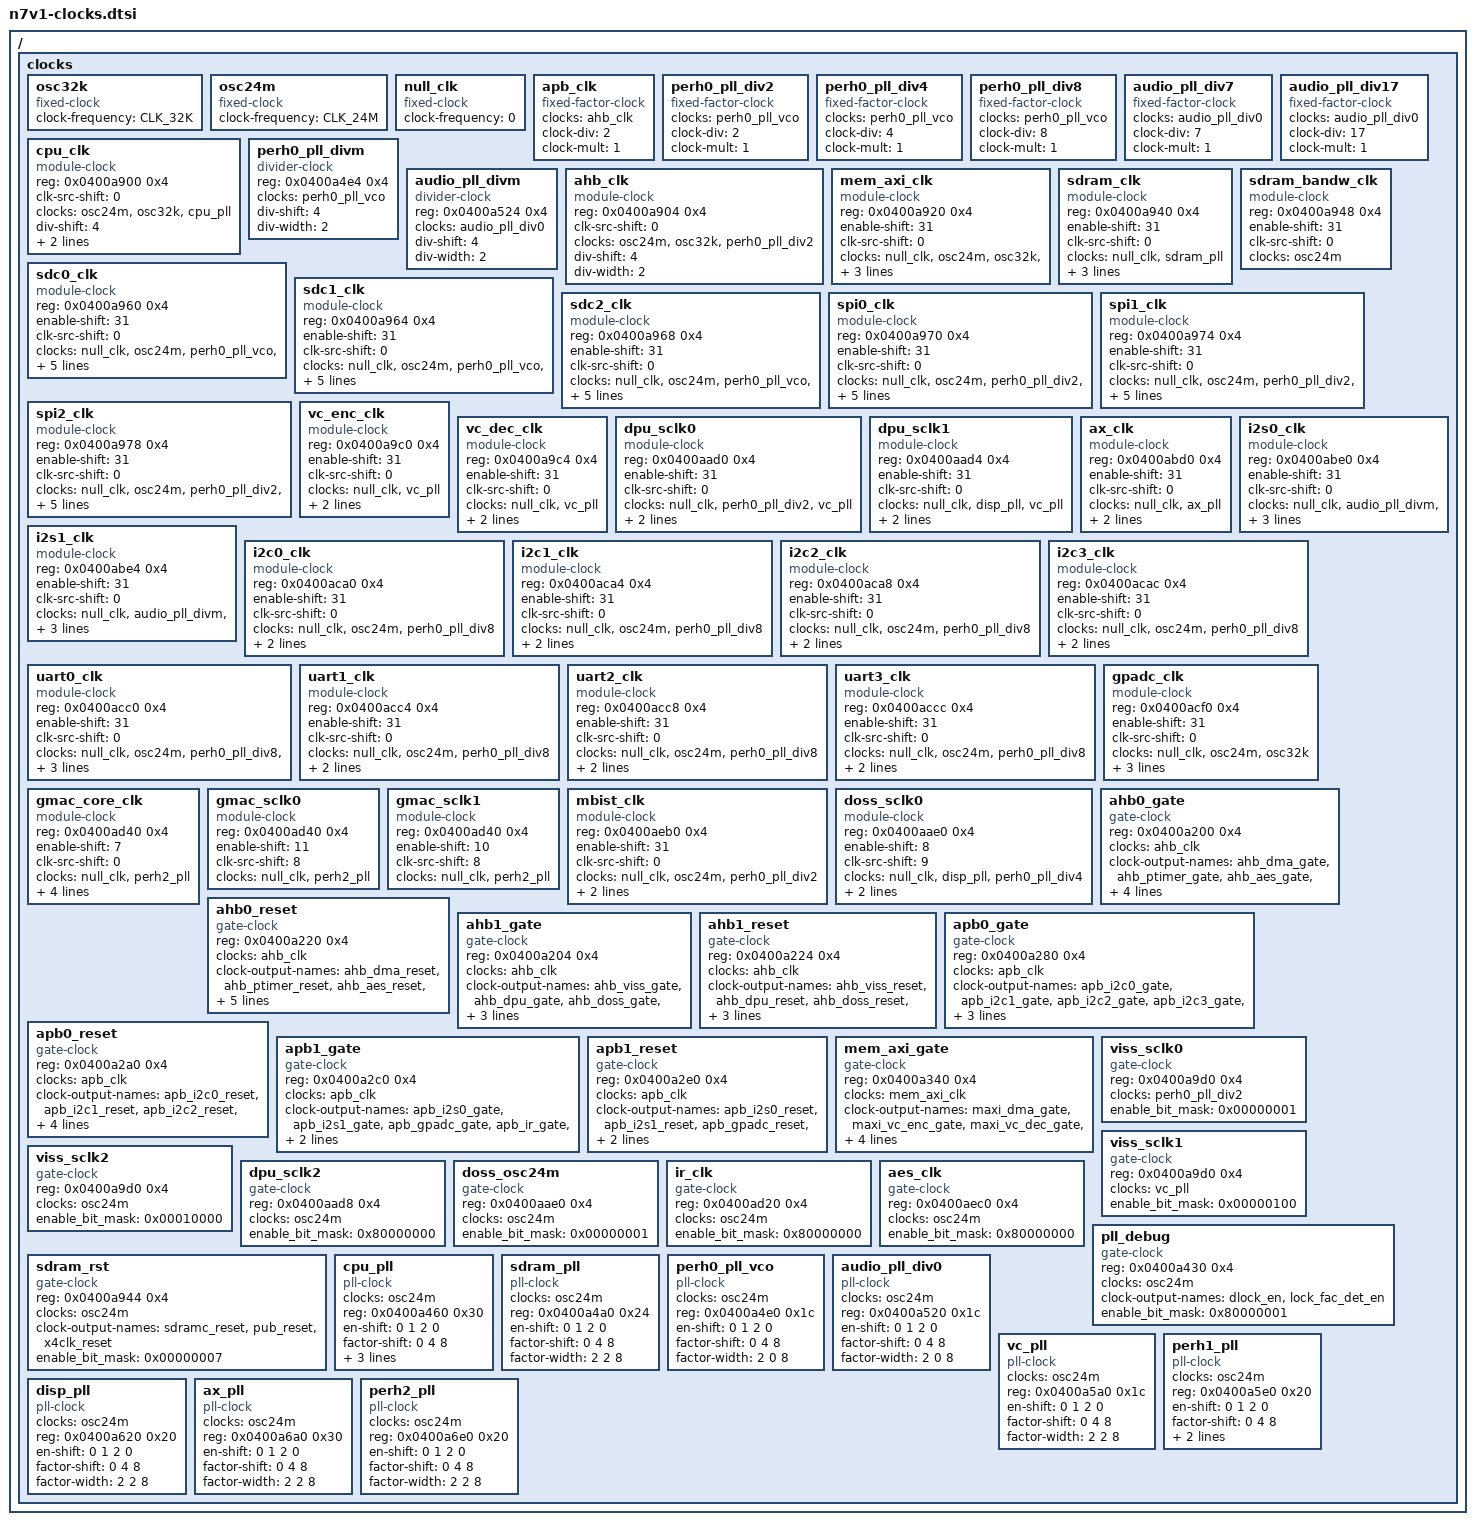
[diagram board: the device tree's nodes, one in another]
/*
 * lombo-n7v1-clocks.dts - clock device tree configurations for N7V1 platform
 *
 * Copyright (C) 2016-2018, LomboTech Co.Ltd.
 * Author: lomboswer <lomboswer@lombotech.com>
 *
 * This program is free software; you can redistribute it and/or modify
 * it under the terms of the GNU General Public License version 2 as
 * published by the Free Software Foundation.
 *
 * This program is distributed in the hope that it will be useful,
 * but WITHOUT ANY WARRANTY; without even the implied warranty of
 * MERCHANTABILITY or FITNESS FOR A PARTICULAR PURPOSE.  See the
 * GNU General Public License for more details.
 *
 * You should have received a copy of the GNU General Public License along
 * with this program; if not, write to the Free Software Foundation, Inc.,
 * 51 Franklin Street, Fifth Floor, Boston, MA 02110-1301 USA.
 */

/ {

/*
 * note: these clocks are not realized now:
 *    hfeosc xtal control register(0x420)
 *    mbias control register(0x424)
 *    usb phy reset control register(0xce0)
 */

clocks {
	#address-cells = <1>;
	#size-cells = <1>;
	ranges;

	/*
	 * fix rate clocks - osc
	 */
	osc32k: osc32k {
		compatible = "fixed-clock";
		#clock-cells = <0>;
		clock-frequency = <CLK_32K>;
	};

	osc24m: osc24m {
		compatible = "fixed-clock";
		#clock-cells = <0>;
		clock-frequency = <CLK_24M>;
	};

	/* used as other clocks' parent, not real clock */
	null_clk: null_clk {
		compatible = "fixed-clock";
		#clock-cells = <0>;
		clock-frequency = <0>;
	};

	/*
	 * fix factor clocks
	 */
	apb_clk: apb_clk {
		compatible = "fixed-factor-clock";
		clocks = <&ahb_clk>;
		#clock-cells = <0>;
		clock-div = <2>;
		clock-mult = <1>;
	};

	perh0_pll_div2: perh0_pll_div2 {
		compatible = "fixed-factor-clock";
		clocks = <&perh0_pll_vco>;
		#clock-cells = <0>;
		clock-div = <2>;
		clock-mult = <1>;
	};

	perh0_pll_div4: perh0_pll_div4 {
		compatible = "fixed-factor-clock";
		clocks = <&perh0_pll_vco>;
		#clock-cells = <0>;
		clock-div = <4>;
		clock-mult = <1>;
	};

	perh0_pll_div8: perh0_pll_div8 {
		compatible = "fixed-factor-clock";
		clocks = <&perh0_pll_vco>;
		#clock-cells = <0>;
		clock-div = <8>;
		clock-mult = <1>;
	};

	audio_pll_div7: audio_pll_div7 {
		compatible = "fixed-factor-clock";
		clocks = <&audio_pll_div0>;
		#clock-cells = <0>;
		clock-div = <7>;
		clock-mult = <1>;
	};

	audio_pll_div17: audio_pll_div17 {
		compatible = "fixed-factor-clock";
		clocks = <&audio_pll_div0>;
		#clock-cells = <0>;
		clock-div = <17>;
		clock-mult = <1>;
	};

	/*
	 * cpu and bus clocks
	 */
	cpu_clk: cpu_clk {
		compatible = "module-clock";
		reg = <0x0400a900 0x4>;
		#clock-cells = <0>;
		clk-src-shift = <0>;
		clocks = <&osc24m>, <&osc32k>, <&cpu_pll>;
		div-shift = <4>;
		div-width = <2>;
		div-table = <0 1
			     1 2
			     2 4>;
	};

	perh0_pll_divm: perh0_pll_divm {
		compatible = "divider-clock";
		reg = <0x0400a4e4 0x4>;
		#clock-cells = <0>;
		clocks = <&perh0_pll_vco>;
		div-shift = <4>;
		div-width = <2>;
	};

	audio_pll_divm: audio_pll_divm {
		compatible = "divider-clock";
		reg = <0x0400a524 0x4>;
		#clock-cells = <0>;
		clocks = <&audio_pll_div0>;
		div-shift = <4>;
		div-width = <2>;
	};

	/* apb_clk is fix-divider-clock */

	/*
	 * module  clocks
	 *
	 * xxx_clk: xxx_clk {			clock name
	 *	compatible = "module-clock";	identify string, should not be changed
	 *	reg = <0x0400a900 0x4>;		the register addr and len
	 *	#clock-cells = <0>;		should be 0
	 *	enable-shift = <xxx>;		optional, enable bit's offset
	 *	clk-src-shift = <0>;		the src clock select bit's offset
	 *	clocks = <&src_clk1>, <&src_clk2>;	parent clocks list
	 *
	 * the below configurations are specific for different modules:
	 *   for clocks with only div0:
	 *	div-shift = <div0_shift>;	bit offset of div0
	 *	div-width = <div0_width>;	bit width of div0
	 *	div-table = <val div val div...>;	optional, div0 table
	 *	  note:	1. if div-table not exist, the division value default
	 *			is (div_val+1), while div_val is read from reg
	 *
	 *   for clocks with div0 and div1:
	 *	div-shift = <div0_shift div1_shift>;	bit offset of div0 and div1
	 *	div-width = <div0_width div1_width>;	bit width of div0 and div1
	 *	div-table0 = <val div val div...>;	optional, div0 table
	 *	div-table1 = <val div val div...>;	optional, div1 table
	 *	  note:	1. if div-table not exist, the division value default
	 *			is (div_val+1), while div_val is read from reg
	 *	freq-div-table = <rate parent_rate div0 div1
	 *		          rate parent_rate div0 div1 ...>;   optional
	 *	  note:	1. freq-div-table is optional
	 *		2. div0/div1 is the division value calculated from the orignal
	 *			reg bits value, but it's NOT the orignal bits value
	 *			eg. div0 is 8 and the orignal bits value is 3 (2^3=8)
	 * };
	 */
	ahb_clk: ahb_clk {
		compatible = "module-clock";
		reg = <0x0400a904 0x4>;
		#clock-cells = <0>;
		clk-src-shift = <0>;
		clocks = <&osc24m>, <&osc32k>,
			<&perh0_pll_div2>;
		div-shift = <4>;
		div-width = <2>;
	};

	mem_axi_clk: mem_axi_clk {
		compatible = "module-clock";
		reg = <0x0400a920 0x4>;
		#clock-cells = <0>;
		enable-shift = <31>;
		clk-src-shift = <0>;
		clocks = <&null_clk>, <&osc24m>,
			<&osc32k>, <&perh0_pll_vco>;
		div-shift = <4>;
		div-width = <2>;
	};

	sdram_clk: sdram_clk {
		compatible = "module-clock";
		reg = <0x0400a940 0x4>;
		#clock-cells = <0>;
		enable-shift = <31>;
		clk-src-shift = <0>;
		clocks = <&null_clk>, <&sdram_pll>;
		div-shift = <4>;
		div-width = <2>;
		div-table = <0 1
			     1 2
			     2 4>;
	};

	sdram_bandw_clk: sdram_bandw_clk {
		compatible = "module-clock";
		reg = <0x0400a948 0x4>;
		#clock-cells = <0>;
		enable-shift = <31>;
		clk-src-shift = <0>;
		clocks = <&osc24m>;
	};

	sdc0_clk: sdc0_clk {
		compatible = "module-clock";
		reg = <0x0400a960 0x4>;
		#clock-cells = <0>;
		enable-shift = <31>;
		clk-src-shift = <0>;
		clocks = <&null_clk>, <&osc24m>,
			<&perh0_pll_vco>, <&perh1_pll>;
		div-shift = <4 8>;
		div-width = <4 4>;
		freq-div-table = <200000    24000000    12  10
				  240000    24000000    10  10
				  400000    24000000    6   10
				  600000    24000000    5   8
				  800000    24000000    5   6
				  24000000  24000000    1   1
				  30000000  600000000   10  2
				  50000000  600000000   6   2
				  60000000  600000000   5   2
				  75000000  600000000   4   2
				  100000000 600000000   3   2
				  104000000 600000000   3   2
				  120000000 600000000   5   1
				  150000000 600000000   2   2
				  200000000 600000000   3   1
				  300000000 600000000   1   2
				  30000000  1188000000  5   8
				  40000000  1188000000  5   6
				  48000000  1188000000  5   5
				  50000000  1188000000  6   4
				  60000000  1188000000  5   4
				  66000000  1188000000  3   6
				  74000000  1188000000  4   4
				  80000000  1188000000  15  1
				  92000000  1188000000  13  1
				  100000000 1188000000  3   4
				  104000000 1188000000  3   4
				  108000000 1188000000  11  1
				  120000000 1188000000  5   2
				  132000000 1188000000  9   1
				  150000000 1188000000  8   1
				  170000000 1188000000  7   1
				  200000000 1188000000  6   1
				  240000000 1188000000  5   1
				  300000000 1188000000  4   1
				  400000000 1188000000  3   1>;
	};

	sdc1_clk: sdc1_clk {
		compatible = "module-clock";
		reg = <0x0400a964 0x4>;
		#clock-cells = <0>;
		enable-shift = <31>;
		clk-src-shift = <0>;
		clocks = <&null_clk>, <&osc24m>,
			<&perh0_pll_vco>, <&perh1_pll>;
		div-shift = <4 8>;
		div-width = <4 4>;
		freq-div-table = <200000    24000000    12  10
				  240000    24000000    10  10
				  400000    24000000    6   10
				  600000    24000000    5   8
				  800000    24000000    5   6
				  24000000  24000000    1   1
				  30000000  600000000   10  2
				  50000000  600000000   6   2
				  60000000  600000000   5   2
				  75000000  600000000   4   2
				  100000000 600000000   3   2
				  104000000 600000000   3   2
				  120000000 600000000   5   1
				  150000000 600000000   2   2
				  200000000 600000000   3   1
				  300000000 600000000   1   2
				  30000000  1188000000  5   8
				  40000000  1188000000  5   6
				  48000000  1188000000  5   5
				  50000000  1188000000  6   4
				  60000000  1188000000  5   4
				  66000000  1188000000  3   6
				  74000000  1188000000  4   4
				  80000000  1188000000  15  1
				  92000000  1188000000  13  1
				  100000000 1188000000  3   4
				  104000000 1188000000  3   4
				  108000000 1188000000  11  1
				  120000000 1188000000  5   2
				  132000000 1188000000  9   1
				  150000000 1188000000  8   1
				  170000000 1188000000  7   1
				  200000000 1188000000  6   1
				  240000000 1188000000  5   1
				  300000000 1188000000  4   1
				  400000000 1188000000  3   1>;
	};

	sdc2_clk: sdc2_clk {
		compatible = "module-clock";
		reg = <0x0400a968 0x4>;
		#clock-cells = <0>;
		enable-shift = <31>;
		clk-src-shift = <0>;
		clocks = <&null_clk>, <&osc24m>,
			<&perh0_pll_vco>, <&perh1_pll>;
		div-shift = <4 8>;
		div-width = <4 4>;
		freq-div-table = <200000    24000000    12  10
				  240000    24000000    10  10
				  400000    24000000    6   10
				  600000    24000000    5   8
				  800000    24000000    5   6
				  24000000  24000000    1   1
				  30000000  600000000   10  2
				  50000000  600000000   6   2
				  60000000  600000000   5   2
				  75000000  600000000   4   2
				  100000000 600000000   3   2
				  104000000 600000000   3   2
				  120000000 600000000   5   1
				  150000000 600000000   2   2
				  200000000 600000000   3   1
				  300000000 600000000   1   2
				  30000000  1188000000  5   8
				  40000000  1188000000  5   6
				  48000000  1188000000  5   5
				  50000000  1188000000  6   4
				  60000000  1188000000  5   4
				  66000000  1188000000  3   6
				  74000000  1188000000  4   4
				  80000000  1188000000  15  1
				  92000000  1188000000  13  1
				  100000000 1188000000  3   4
				  104000000 1188000000  3   4
				  108000000 1188000000  11  1
				  120000000 1188000000  5   2
				  132000000 1188000000  9   1
				  150000000 1188000000  8   1
				  170000000 1188000000  7   1
				  200000000 1188000000  6   1
				  240000000 1188000000  5   1
				  300000000 1188000000  4   1
				  400000000 1188000000  3   1>;
	};

	spi0_clk: spi0_clk {
		compatible = "module-clock";
		reg = <0x0400a970 0x4>;
		#clock-cells = <0>;
		enable-shift = <31>;
		clk-src-shift = <0>;
		clocks = <&null_clk>, <&osc24m>,
			<&perh0_pll_div2>, <&perh1_pll>;
		div-shift = <4 8>;
		div-width = <3 4>;
		freq-div-table = <4000000    24000000   1   6
				  6000000    24000000   1   4
				  8000000    24000000   1   3
				  12000000   24000000   1   2
				  24000000   24000000   1   1
				  25000000   594000000  6   4
				  30000000   594000000  5   4
				  37500000   594000000  4   4
				  40000000   594000000  3   5
				  50000000   594000000  3   4
				  60000000   594000000  5   2
				  75000000   594000000  2   4
				  100000000  594000000  3   2
				  120000000  594000000  1   5
				  150000000  594000000  1   4
				  200000000  594000000  1   3>;
	};

	spi1_clk: spi1_clk {
		compatible = "module-clock";
		reg = <0x0400a974 0x4>;
		#clock-cells = <0>;
		enable-shift = <31>;
		clk-src-shift = <0>;
		clocks = <&null_clk>, <&osc24m>,
			<&perh0_pll_div2>, <&perh1_pll>;
		div-shift = <4 8>;
		div-width = <3 4>;
		freq-div-table = <4000000    24000000   1   6
				  6000000    24000000   1   4
				  8000000    24000000   1   3
				  12000000   24000000   1   2
				  24000000   24000000   1   1
				  25000000   594000000  6   4
				  30000000   594000000  5   4
				  37500000   594000000  4   4
				  40000000   594000000  3   5
				  50000000   594000000  3   4
				  60000000   594000000  5   2
				  75000000   594000000  2   4
				  100000000  594000000  3   2
				  120000000  594000000  1   5
				  150000000  594000000  1   4
				  200000000  594000000  1   3>;
	};

	spi2_clk: spi2_clk {
		compatible = "module-clock";
		reg = <0x0400a978 0x4>;
		#clock-cells = <0>;
		enable-shift = <31>;
		clk-src-shift = <0>;
		clocks = <&null_clk>, <&osc24m>,
			<&perh0_pll_div2>, <&perh1_pll>;
		div-shift = <4 8>;
		div-width = <3 4>;
		freq-div-table = <4000000    24000000   1   6
				  6000000    24000000   1   4
				  8000000    24000000   1   3
				  12000000   24000000   1   2
				  24000000   24000000   1   1
				  25000000   594000000  6   4
				  30000000   594000000  5   4
				  37500000   594000000  4   4
				  40000000   594000000  3   5
				  50000000   594000000  3   4
				  60000000   594000000  5   2
				  75000000   594000000  2   4
				  100000000  594000000  3   2
				  120000000  594000000  1   5
				  150000000  594000000  1   4
				  200000000  594000000  1   3>;
	};

	vc_enc_clk: vc_enc_clk {
		compatible = "module-clock";
		reg = <0x0400a9c0 0x4>;
		#clock-cells = <0>;
		enable-shift = <31>;
		clk-src-shift = <0>;
		clocks = <&null_clk>, <&vc_pll>;
		div-shift = <4>;
		div-width = <4>;
	};

	vc_dec_clk: vc_dec_clk {
		compatible = "module-clock";
		reg = <0x0400a9c4 0x4>;
		#clock-cells = <0>;
		enable-shift = <31>;
		clk-src-shift = <0>;
		clocks = <&null_clk>, <&vc_pll>;
		div-shift = <4>;
		div-width = <4>;
	};

	/* viss_sclk0/1/2 are gate clock */

	dpu_sclk0: dpu_sclk0 {
		compatible = "module-clock";
		reg = <0x0400aad0 0x4>;
		#clock-cells = <0>;
		enable-shift = <31>;
		clk-src-shift = <0>;
		clocks = <&null_clk>, <&perh0_pll_div2>, <&vc_pll>;
		div-shift = <4>;
		div-width = <4>;
	};

	dpu_sclk1: dpu_sclk1 {
		compatible = "module-clock";
		reg = <0x0400aad4 0x4>;
		#clock-cells = <0>;
		enable-shift = <31>;
		clk-src-shift = <0>;
		clocks = <&null_clk>, <&disp_pll>, <&vc_pll>;
		div-shift = <4>;
		div-width = <4>;
	};

	/* dpu_sclk2 is gate clock */

	ax_clk: ax_clk {
		compatible = "module-clock";
		reg = <0x0400abd0 0x4>;
		#clock-cells = <0>;
		enable-shift = <31>;
		clk-src-shift = <0>;
		clocks = <&null_clk>, <&ax_pll>;
		div-shift = <4>;
		div-width = <3>;
	};

	i2s0_clk: i2s0_clk {
		compatible = "module-clock";
		reg = <0x0400abe0 0x4>;
		#clock-cells = <0>;
		enable-shift = <31>;
		clk-src-shift = <0>;
		clocks = <&null_clk>, <&audio_pll_divm>,
			<&audio_pll_div7>, <&audio_pll_div17>;
		div-shift = <4>;
		div-width = <3>;
	};

	i2s1_clk: i2s1_clk {
		compatible = "module-clock";
		reg = <0x0400abe4 0x4>;
		#clock-cells = <0>;
		enable-shift = <31>;
		clk-src-shift = <0>;
		clocks = <&null_clk>, <&audio_pll_divm>,
			<&audio_pll_div7>, <&audio_pll_div17>;
		div-shift = <4>;
		div-width = <3>;
	};

	i2c0_clk: i2c0_clk {
		compatible = "module-clock";
		reg = <0x0400aca0 0x4>;
		#clock-cells = <0>;
		enable-shift = <31>;
		clk-src-shift = <0>;
		clocks = <&null_clk>, <&osc24m>, <&perh0_pll_div8>;
		div-shift = <4>;
		div-width = <3>;
	};

	i2c1_clk: i2c1_clk {
		compatible = "module-clock";
		reg = <0x0400aca4 0x4>;
		#clock-cells = <0>;
		enable-shift = <31>;
		clk-src-shift = <0>;
		clocks = <&null_clk>, <&osc24m>, <&perh0_pll_div8>;
		div-shift = <4>;
		div-width = <3>;
	};

	i2c2_clk: i2c2_clk {
		compatible = "module-clock";
		reg = <0x0400aca8 0x4>;
		#clock-cells = <0>;
		enable-shift = <31>;
		clk-src-shift = <0>;
		clocks = <&null_clk>, <&osc24m>, <&perh0_pll_div8>;
		div-shift = <4>;
		div-width = <3>;
	};

	i2c3_clk: i2c3_clk {
		compatible = "module-clock";
		reg = <0x0400acac 0x4>;
		#clock-cells = <0>;
		enable-shift = <31>;
		clk-src-shift = <0>;
		clocks = <&null_clk>, <&osc24m>, <&perh0_pll_div8>;
		div-shift = <4>;
		div-width = <3>;
	};

	uart0_clk: uart0_clk {
		compatible = "module-clock";
		reg = <0x0400acc0 0x4>;
		#clock-cells = <0>;
		enable-shift = <31>;
		clk-src-shift = <0>;
		clocks = <&null_clk>, <&osc24m>, <&perh0_pll_div8>, <&osc32k>;
		div-shift = <4>;
		div-width = <3>;
	};

	uart1_clk: uart1_clk {
		compatible = "module-clock";
		reg = <0x0400acc4 0x4>;
		#clock-cells = <0>;
		enable-shift = <31>;
		clk-src-shift = <0>;
		clocks = <&null_clk>, <&osc24m>, <&perh0_pll_div8>;
		div-shift = <4>;
		div-width = <3>;
	};

	uart2_clk: uart2_clk {
		compatible = "module-clock";
		reg = <0x0400acc8 0x4>;
		#clock-cells = <0>;
		enable-shift = <31>;
		clk-src-shift = <0>;
		clocks = <&null_clk>, <&osc24m>, <&perh0_pll_div8>;
		div-shift = <4>;
		div-width = <3>;
	};

	uart3_clk: uart3_clk {
		compatible = "module-clock";
		reg = <0x0400accc 0x4>;
		#clock-cells = <0>;
		enable-shift = <31>;
		clk-src-shift = <0>;
		clocks = <&null_clk>, <&osc24m>, <&perh0_pll_div8>;
		div-shift = <4>;
		div-width = <3>;
	};

	gpadc_clk: gpadc_clk {
		compatible = "module-clock";
		reg = <0x0400acf0 0x4>;
		#clock-cells = <0>;
		enable-shift = <31>;
		clk-src-shift = <0>;
		clocks = <&null_clk>, <&osc24m>, <&osc32k>;
		div-shift = <4>;
		div-width = <1>;
		div-table = <0 1
			     1 32>;
	};

	/* ir_clk is gate clock */

	gmac_core_clk: gmac_core_clk {
		compatible = "module-clock";
		reg = <0x0400ad40 0x4>;
		#clock-cells = <0>;
		enable-shift = <7>;
		clk-src-shift = <0>;
		clocks = <&null_clk>, <&perh2_pll>;
		div-shift = <4>;
		div-width = <3>;
		freq-table = <250000000 500000000 2
			      167000000 500000000 3
			      100000000 500000000 5>;
	};

	gmac_sclk0: gmac_sclk0 {
		compatible = "module-clock";
		reg = <0x0400ad40 0x4>;
		#clock-cells = <0>;
		enable-shift = <11>;
		clk-src-shift = <8>;
		clocks = <&null_clk>, <&perh2_pll>;
	};

	gmac_sclk1: gmac_sclk1 {
		compatible = "module-clock";
		reg = <0x0400ad40 0x4>;
		#clock-cells = <0>;
		enable-shift = <10>;
		clk-src-shift = <8>;
		clocks = <&null_clk>, <&perh2_pll>;
	};

	mbist_clk: mbist_clk {
		compatible = "module-clock";
		reg = <0x0400aeb0 0x4>;
		#clock-cells = <0>;
		enable-shift = <31>;
		clk-src-shift = <0>;
		clocks = <&null_clk>, <&osc24m>, <&perh0_pll_div2>;
		div-shift = <4>;
		div-width = <4>;
	};

	doss_sclk0: doss_sclk0 {
		compatible = "module-clock";
		reg = <0x0400aae0 0x4>;
		#clock-cells = <0>;
		enable-shift = <8>;
		clk-src-shift = <9>;
		clocks = <&null_clk>, <&disp_pll>, <&perh0_pll_div4>;
		div-shift = <12>;
		div-width = <4>;
	};

	/* aes_clk is gate clock */

	/*
	 * gate  clocks
	 */
	ahb0_gate: ahb0_gate {
		compatible = "gate-clock";
		reg = <0x0400a200 0x4>;
		#clock-cells = <1>;
		clocks = <&ahb_clk>;
		clock-output-names = "ahb_dma_gate",
			"ahb_ptimer_gate", "ahb_aes_gate",
			"ahb_sdram_gate", "ahb_sdc0_gate",
			"ahb_sdc1_gate", "ahb_sdc2_gate",
			"ahb_spi0_gate", "ahb_spi1_gate",
			"ahb_spi2_gate";
		enable_bit_mask = <0x00ef0043>;
	};

	ahb0_reset: ahb0_reset {
		compatible = "gate-clock";
		reg = <0x0400a220 0x4>;
		#clock-cells = <1>;
		clocks = <&ahb_clk>;
		clock-output-names = "ahb_dma_reset",
			"ahb_ptimer_reset", "ahb_aes_reset",
			"ahb_sdram_reset", "ahb_sdc0_reset",
			"ahb_sdc1_reset", "ahb_sdc2_reset",
			"ahb_spi0_reset", "ahb_spi1_reset",
			"ahb_spi2_reset";
		enable_bit_mask = <0x00ef0043>;
	};

	ahb1_gate: ahb1_gate {
		compatible = "gate-clock";
		reg = <0x0400a204 0x4>;
		#clock-cells = <1>;
		clocks = <&ahb_clk>;
		clock-output-names = "ahb_viss_gate",
			"ahb_dpu_gate", "ahb_doss_gate",
			"ahb_vc_dec_gate", "ahb_vc_enc_gate",
			"ahb_ax_gate", "ahb_usb_gate",
			"ahb_gmac_gate";
		enable_bit_mask = <0x00053815>;
	};

	ahb1_reset: ahb1_reset {
		compatible = "gate-clock";
		reg = <0x0400a224 0x4>;
		#clock-cells = <1>;
		clocks = <&ahb_clk>;
		clock-output-names = "ahb_viss_reset",
			"ahb_dpu_reset", "ahb_doss_reset",
			"ahb_vc_dec_reset", "ahb_vc_enc_reset",
			"ahb_ax_reset", "ahb_usb_reset",
			"ahb_gmac_reset";
		enable_bit_mask = <0x00053815>;
	};

	apb0_gate: apb0_gate {
		compatible = "gate-clock";
		reg = <0x0400a280 0x4>;
		#clock-cells = <1>;
		clocks = <&apb_clk>;
		clock-output-names = "apb_i2c0_gate",
			"apb_i2c1_gate", "apb_i2c2_gate",
			"apb_i2c3_gate", "apb_uart0_gate",
			"apb_uart1_gate", "apb_uart2_gate",
			"apb_uart3_gate";
		enable_bit_mask = <0x00000f0f>;
	};

	apb0_reset: apb0_reset {
		compatible = "gate-clock";
		reg = <0x0400a2a0 0x4>;
		#clock-cells = <1>;
		clocks = <&apb_clk>;
		clock-output-names = "apb_i2c0_reset",
			"apb_i2c1_reset", "apb_i2c2_reset",
			"apb_i2c3_reset", "apb_uart0_reset",
			"apb_uart1_reset", "apb_uart2_reset",
			"apb_uart3_reset";
		enable_bit_mask = <0x00000f0f>;
	};

	apb1_gate: apb1_gate {
		compatible = "gate-clock";
		reg = <0x0400a2c0 0x4>;
		#clock-cells = <1>;
		clocks = <&apb_clk>;
		clock-output-names = "apb_i2s0_gate",
			"apb_i2s1_gate", "apb_gpadc_gate",
			"apb_ir_gate", "apb_gpio_gate";
		enable_bit_mask = <0x0000034C>;
	};

	apb1_reset: apb1_reset {
		compatible = "gate-clock";
		reg = <0x0400a2e0 0x4>;
		#clock-cells = <1>;
		clocks = <&apb_clk>;
		clock-output-names = "apb_i2s0_reset",
			"apb_i2s1_reset", "apb_gpadc_reset",
			"apb_ir_reset", "apb_gpio_reset";
		enable_bit_mask = <0x0000034C>;
	};

	mem_axi_gate: mem_axi_gate {
		compatible = "gate-clock";
		reg = <0x0400a340 0x4>;
		#clock-cells = <1>;
		clocks = <&mem_axi_clk>;
		clock-output-names = "maxi_dma_gate",
			"maxi_vc_enc_gate", "maxi_vc_dec_gate",
			"maxi_viss0_gate", "maxi_viss1_gate",
			"maxi_dpu_gate", "maxi_doss_gate",
			"maxi_ax_gate", "maxi_gmac_gate";
		enable_bit_mask = <0x00041537>;
	};

	viss_sclk0: viss_sclk0 {
		compatible = "gate-clock";
		reg = <0x0400a9d0 0x4>;
		#clock-cells = <0>;
		clocks = <&perh0_pll_div2>;
		enable_bit_mask = <0x00000001>;
	};

	viss_sclk1: viss_sclk1 {
		compatible = "gate-clock";
		reg = <0x0400a9d0 0x4>;
		#clock-cells = <0>;
		clocks = <&vc_pll>;
		enable_bit_mask = <0x00000100>;
	};

	viss_sclk2: viss_sclk2 {
		compatible = "gate-clock";
		reg = <0x0400a9d0 0x4>;
		#clock-cells = <0>;
		clocks = <&osc24m>;
		enable_bit_mask = <0x00010000>;
	};

	dpu_sclk2: dpu_sclk2 {
		compatible = "gate-clock";
		reg = <0x0400aad8 0x4>;
		#clock-cells = <0>;
		clocks = <&osc24m>;
		enable_bit_mask = <0x80000000>;
	};

	doss_osc24m: doss_osc24m {
		compatible = "gate-clock";
		reg = <0x0400aae0 0x4>;
		#clock-cells = <0>;
		clocks = <&osc24m>;
		enable_bit_mask = <0x00000001>;
	};

	ir_clk: ir_clk {
		compatible = "gate-clock";
		reg = <0x0400ad20 0x4>;
		#clock-cells = <0>;
		clocks = <&osc24m>;
		enable_bit_mask = <0x80000000>;
	};

	aes_clk: aes_clk {
		compatible = "gate-clock";
		reg = <0x0400aec0 0x4>;
		#clock-cells = <0>;
		clocks = <&osc24m>;
		enable_bit_mask = <0x80000000>;
	};

	pll_debug: pll_debug {
		compatible = "gate-clock";
		reg = <0x0400a430 0x4>;
		#clock-cells = <1>;
		clocks = <&osc24m>;
		clock-output-names = "dlock_en", "lock_fac_det_en";
		enable_bit_mask = <0x80000001>;
	};

	sdram_rst: sdram_rst {
		compatible = "gate-clock";
		reg = <0x0400a944 0x4>;
		#clock-cells = <1>;
		clocks = <&osc24m>;
		clock-output-names = "sdramc_reset", "pub_reset",
					"x4clk_reset";
		enable_bit_mask = <0x00000007>;
	};

	/*
	 * pll clocks
	 *
	 * xxx_pll: xxx_pll {			clock name
	 *	compatible = "pll-clock";	identify string, should not be changed
	 *	#clock-cells = <0>;		should be 0
	 *	clocks = <&osc24m>;		all pll's parent is osc24m
	 *	reg = <0x0400a460 0x24>;	reg addr and length
	 *	    note: 1. reg list order: enable, factor, tune0, test,
	 *			status, mode, N-factor, tune1, tune2.
	 *		  2. the last regs(one or more) may be not exist according
	 *			to spec, eg: if tune1 and tune2 reg not exist, length
	 *			should be 0x1c
	 *
	 *	en-shift = <enp enm oen lock>;	bit index for pll enable operation
	 *	    note: 1. bit index for cpu_enp, cpu_enm, cpu_oen and lock status
	 *		  2. lock status is in status reg, the others are in enable reg
	 *
	 *	factor-shift = <prev post n>;	bit index for prediv postdiv and factor
	 *	factor-width = <prev post n>;	bit width for prediv postdiv and factor
	 *
	 * the below configurations are optional:
	 *	freq-table = <freq parent_freq n prev_div post_div
	 *		      freq parent_freq n prev_div post_div ...>; freq div table
	 *	    note: 1. n is the factor N. parent_freq is 24000000(osc24m)
	 *		  2. prev_div/post_div is the division value calculated from
	 *			the orignal reg bits value, but it's NOT the orignal
	 *			bits value. eg. prev_div is 4 and orignal bits value
	 *			is 3(3+1=4)
	 *	div-table0 = <val div val div...>;	prediv table
	 *	div-table1 = <val div val div...>;	postdiv table
	 * };
	 */
	cpu_pll: cpu_pll {
		compatible = "pll-clock";
		#clock-cells = <0>;
		clocks = <&osc24m>;
		reg = <0x0400a460 0x30>;
		en-shift = <0 1 2 0>;
		factor-shift = <0 4 8>;
		factor-width = <2 2 8>;
		freq-table = <312000000  24000000 13 1 1
			      408000000  24000000 17 1 1
			      600000000  24000000 25 1 1
			      720000000  24000000 30 1 1
			      816000000  24000000 34 1 1
			      912000000  24000000 38 1 1
			      1008000000 24000000 42 1 1>;
	};

	sdram_pll: sdram_pll {
		compatible = "pll-clock";
		#clock-cells = <0>;
		clocks = <&osc24m>;
		reg = <0x0400a4a0 0x24>;
		en-shift = <0 1 2 0>;
		factor-shift = <0 4 8>;
		factor-width = <2 2 8>;
		/* freq-table = <xxx>; */
	};

	/* perh0 pll with POST_DIV reg bit field bypassed */
	perh0_pll_vco: perh0_pll_vco {
		compatible = "pll-clock";
		#clock-cells = <0>;
		clocks = <&osc24m>;
		reg = <0x0400a4e0 0x1c>;
		en-shift = <0 1 2 0>;
		factor-shift = <0 4 8>;
		/*
		 * note: in order to bypass POST_DIV reg bit field, we here
		 * set postdiv width to 0, so:
		 *   when get clock rate, clock_pll_recalc_rate will bypass
		 *     the POST_DIV reg bit field (the post division got is
		 *     always 1);
		 *   when set clock rate, clock_pll_set_rate will bypass
		 *     the POST_DIV reg bit field (not change the field value)
		 */
		factor-width = <2 0 8>;
		/* freq-table = <xxx>; */
	};

	/* audio pll with POST_DIV reg bit field bypassed */
	audio_pll_div0: audio_pll_div0 {
		compatible = "pll-clock";
		#clock-cells = <0>;
		clocks = <&osc24m>;
		reg = <0x0400a520 0x1c>;
		en-shift = <0 1 2 0>;
		factor-shift = <0 4 8>;
		/*
		 * note: in order to bypass POST_DIV reg bit field, we here
		 * set postdiv width to 0, so:
		 *   when get clock rate, clock_pll_recalc_rate will bypass
		 *     the POST_DIV reg bit field (the post division got is
		 *     always 1);
		 *   when set clock rate, clock_pll_set_rate will bypass
		 *     the POST_DIV reg bit field (not change the field value)
		 */
		factor-width = <2 0 8>;
		/*
		 * note: audio pll does not need freq-table,
		 * its freq div table is in source (special)
		 */
		/* freq-table = <xxx>; */
	};

	vc_pll: vc_pll {
		compatible = "pll-clock";
		#clock-cells = <0>;
		clocks = <&osc24m>;
		reg = <0x0400a5a0 0x1c>;
		en-shift = <0 1 2 0>;
		factor-shift = <0 4 8>;
		factor-width = <2 2 8>;
		/* freq-table = <xxx>; */
	};

	perh1_pll: perh1_pll {
		compatible = "pll-clock";
		#clock-cells = <0>;
		clocks = <&osc24m>;
		reg = <0x0400a5e0 0x20>;
		en-shift = <0 1 2 0>;
		factor-shift = <0 4 8>;
		factor-width = <2 2 8>;
		freq-table = <600000000  24000000 25 1 1>;
	};

	disp_pll: disp_pll {
		compatible = "pll-clock";
		#clock-cells = <0>;
		clocks = <&osc24m>;
		reg = <0x0400a620 0x20>;
		en-shift = <0 1 2 0>;
		factor-shift = <0 4 8>;
		factor-width = <2 2 8>;
		/* freq-table = <xxx>; */
	};

	ax_pll: ax_pll {
		compatible = "pll-clock";
		#clock-cells = <0>;
		clocks = <&osc24m>;
		reg = <0x0400a6a0 0x30>;
		en-shift = <0 1 2 0>;
		factor-shift = <0 4 8>;
		factor-width = <2 2 8>;
		/* freq-table = <xxx>; */
	};

	perh2_pll: perh2_pll {
		compatible = "pll-clock";
		#clock-cells = <0>;
		clocks = <&osc24m>;
		reg = <0x0400a6e0 0x20>;
		en-shift = <0 1 2 0>;
		factor-shift = <0 4 8>;
		factor-width = <2 2 8>;
		/* freq-table = <xxx>; */
	};
};

};
